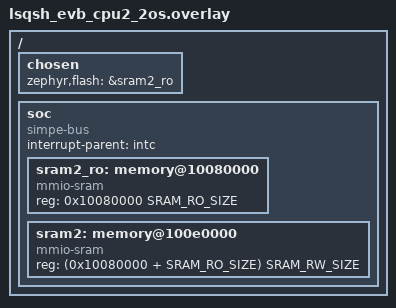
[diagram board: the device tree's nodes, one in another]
/*
 * Copyright (c) 2025 linkedsemi
 * SPDX-License-Identifier: Apache-2.0
 */

#define SRAM_TOTAL_SIZE DT_SIZE_K(768)
#define SRAM_MBOX_SIZE DT_SIZE_K(4)
#define SRAM_SHMEM_SIZE DT_SIZE_K(4)
#define SRAM_RO_SIZE    DT_SIZE_K(384)
#define SRAM_RW_SIZE    (SRAM_TOTAL_SIZE - SRAM_RO_SIZE - SRAM_MBOX_SIZE - SRAM_SHMEM_SIZE)

/ {
    chosen {
        zephyr,flash = &sram2_ro;
    };

    soc {
        compatible = "simpe-bus";
        #address-cells = <1>;
        #size-cells = <1>;
        interrupt-parent = <&intc>;

        /delete-node/ memory@10080000;
        sram2_ro: memory@10080000 {
            compatible = "mmio-sram";
            reg = <0x10080000 SRAM_RO_SIZE>;
        };

        sram2: memory@100e0000 {
            compatible = "mmio-sram";
            reg = <(0x10080000 + SRAM_RO_SIZE) SRAM_RW_SIZE>;
        };
    };
};
